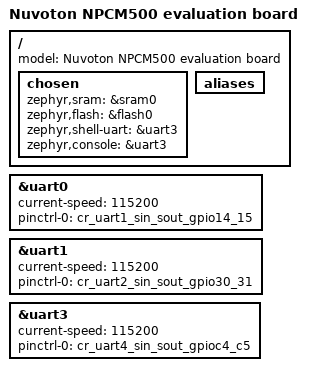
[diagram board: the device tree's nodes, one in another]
/*
 * Copyright (c) 2026 Nuvoton Technology Corporation.
 *
 * SPDX-License-Identifier: Apache-2.0
 */

/dts-v1/;

#include <nuvoton/npcm500.dtsi>

/ {
	model = "Nuvoton NPCM500 evaluation board";

	chosen {
		zephyr,sram = &sram0;
		zephyr,flash = &flash0;
		zephyr,shell-uart = &uart3;
		zephyr,console = &uart3;
	};

	aliases {};
};

&uart0 {
	status = "okay";
	current-speed = <115200>;
	pinctrl-0 = <&cr_uart1_sin_sout_gpio14_15>;
	pinctrl-names = "default";
};

&uart1 {
	status = "okay";
	current-speed = <115200>;
	pinctrl-0 = <&cr_uart2_sin_sout_gpio30_31>;
	pinctrl-names = "default";
};

&uart3 {
	status = "okay";
	current-speed = <115200>;
	pinctrl-0 = <&cr_uart4_sin_sout_gpioc4_c5>;
	pinctrl-names = "default";
};
